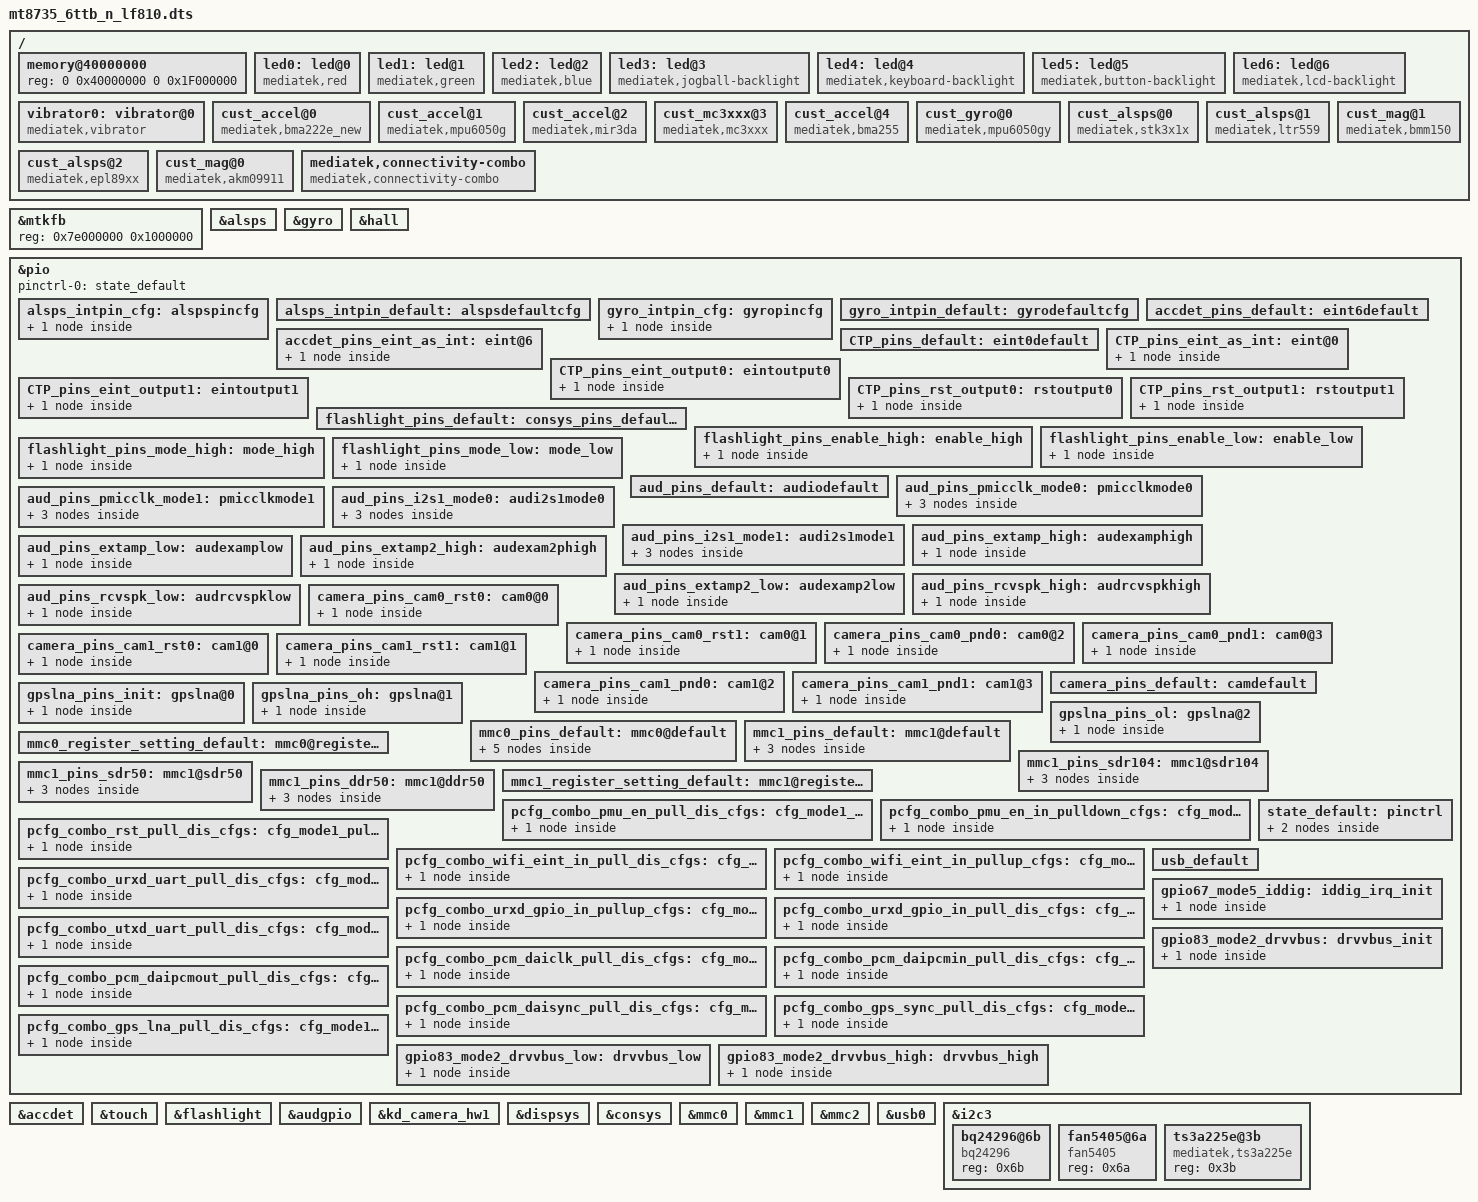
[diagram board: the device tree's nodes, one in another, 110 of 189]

/dts-v1/;

#include "mt6735.dtsi"

#include "cust.dtsi"
#include "cust_eint.dtsi"
#include "mt8735_6ttb_n_bat_setting.dtsi"

/ {
	memory@40000000 {
		device_type = "memory";
		reg = <0 0x40000000 0 0x1F000000>;
	};

	led0:led@0 {
		compatible = "mediatek,red";
		led_mode = <3>;
		data = <1>;
		pwm_config = <0 0 0 0 0>;
	};
	led1:led@1 {
		compatible = "mediatek,green";
		led_mode = <3>;
		data = <2>;
		pwm_config = <0 0 0 0 0>;
	};
	led2:led@2 {
		compatible = "mediatek,blue";
		led_mode = <3>;
		data = <2>;
		pwm_config = <0 0 0 0 0>;
	};
	led3:led@3 {
		compatible = "mediatek,jogball-backlight";
		led_mode = <0>;
		data = <1>;
		pwm_config = <0 0 0 0 0>;
	};
	led4:led@4 {
		compatible = "mediatek,keyboard-backlight";
		led_mode = <0>;
		data = <1>;
		pwm_config = <0 0 0 0 0>;
	};
	led5:led@5 {
		compatible = "mediatek,button-backlight";
		led_mode = <0>;
		data = <1>;
		pwm_config = <0 0 0 0 0>;
	};
	led6:led@6 {
		compatible = "mediatek,lcd-backlight";
		led_mode = <5>;
		data = <1>;
		pwm_config = <0 0 0 0 0>;
	};
	vibrator0:vibrator@0 {
		compatible = "mediatek,vibrator";
		vib_timer = <25>;
		vib_limit = <9>;
		vib_vol= <5>;
	};
	cust_accel@0 {
		compatible = "mediatek,bma222e_new";
		i2c_num = <2>;
		i2c_addr = <0x18 0 0 0>;
		direction = <4>;
		power_id = <0xffff>;
		power_vol = <0>;
		firlen = <16>;
		is_batch_supported = <0>;
	};
        cust_accel@1 {
                compatible = "mediatek,mpu6050g";
                i2c_num = <2>;
                i2c_addr = <0x68 0 0 0>;
                direction = <5>;
                power_id = <0xffff>;
                power_vol = <0>;
                firlen = <16>;
                is_batch_supported = <0>;
        };
        cust_accel@2 {
               compatible = "mediatek,mir3da";
               i2c_num = <2>;
               i2c_addr = <0x26 0 0 0>;
               direction = <7>;             
               power_id = <0xffff>;
               power_vol = <0>;
               firlen = <16>;
               is_batch_supported = <0>;
       };
        cust_mc3xxx@3 {
               compatible = "mediatek,mc3xxx";
               i2c_num = <2>;
               i2c_addr = <0x4c 0 0 0>;
               direction = <4>;
               power_id = <0xffff>;
               power_vol = <0>;
               firlen = <0>;
               is_batch_supported = <0>;
        };
	cust_accel@4 {
		compatible = "mediatek,bma255";
		i2c_num = <2>;
		i2c_addr = <0x10 0 0 0>;
		direction = <4>;
		power_id = <0xffff>;
		power_vol = <0>;
		firlen = <16>;
		is_batch_supported = <0>;
	};
        cust_gyro@0 {
                compatible = "mediatek,mpu6050gy";
                i2c_num = <2>;
                i2c_addr = <0x68 0 0 0>;
                direction = <7>;
                power_id = <0xffff>;
                power_vol = <0>;
                firlen = <16>;
                is_batch_supported = <0>;
        };
        cust_alsps@0 {
                compatible = "mediatek,stk3x1x";
                i2c_num = <2>;
                i2c_addr = <0x48 0 0 0>;
                power_id = <0xffff>;
                power_vol = <0>;
               als_level = <5 9 36 59 82 132 205 273 500 845 1136 1545 2364 4655 6982>;
               als_value= <90 120 145 225 300 550 930 1250 1700 2600 5120 7680 10240 15360 20360 25360>;
               polling_mode_ps = <1>;
               polling_mode_als = <1>;
               ps_threshold_high = <1700>;
               ps_threshold_low = <1500>;
               is_batch_supported_ps = <0>;
               is_batch_supported_als = <0>;
        };
        cust_alsps@1 {
                compatible = "mediatek,ltr559";
                i2c_num = <2>;
                i2c_addr = <0x23 0 0 0>;
		power_id = <0xffff>;
		power_vol = <0>;
               als_level = <5 9 36 59 82 132 205 273 500 845 1136 1545 2364 4655 6982>;
               als_value= <90 120 145 225 300 550 930 1250 1700 2600 5120 7680 10240 15360 20360 25360>;
               polling_mode_ps = <1>;
               polling_mode_als = <1>;
               ps_threshold_high = <1700>;
               ps_threshold_low = <1500>;
		is_batch_supported_ps = <0>;
		is_batch_supported_als = <0>;
	};
	cust_alsps@2 {
        compatible = "mediatek,epl89xx";
        i2c_num = <2>;
        i2c_addr = <0x82 0 0 0>;
        power_id = <0xffff>;
        power_vol = <0>;
        als_level = <20  45  70  90  150  300  500  700  1150  2250  4500  8000  15000  30000  50000>;
        als_value= <10  30  60  80  100  200  400  600  800  1500  3000  6000  10000  20000  40000  60000>;
        polling_mode_ps = <1>;
        polling_mode_als = <1>;
        ps_threshold_high = <4000>;
        ps_threshold_low = <3000>;
        is_batch_supported_ps = <0>;
        is_batch_supported_als = <0>;
    };
	cust_mag@0 {
		compatible				= "mediatek,akm09911";
		i2c_num					= <2>;
		i2c_addr				= <0x0D 0 0 0>;
		direction				= <1>;
		power_id				= <0xffff>;
		power_vol				= <0>;
		is_batch_supported	= <0>;
	};
	cust_mag@1 {
		compatible				= "mediatek,bmm150";
		i2c_num				= <2>;
		i2c_addr				= <0x12 0 0 0>;
		direction				= <1>;
		power_id				= <0xffff>;
		power_vol				= <0>;
		is_batch_supported	= <0>;
	};
/* Connectivity */
	mediatek,connectivity-combo {
		compatible = "mediatek,connectivity-combo";
		/*gpio_combo_ldo_en_pin = <&pio 0xffff 0>;	/*0) GPIO_COMBO_LDO_EN_PIN */
		/*gpio_combo_pmuv28_en_pin = <&pio 0xffff 0>;	/* 1) GPIO_COMBO_PMUV28_EN_PIN */
		gpio_combo_pmu_en_pin = <&pio 21 0>;		/* 2) GPIO_COMBO_PMU_EN_PIN */
		gpio_combo_rst_pin = <&pio 186 0>;		/* 3) GPIO_COMBO_RST_PIN pin */
		/*gpio_combo_bgf_eint_pin = <&pio 0xffff 0>;	/* 4) GPIO_COMBO_BGF_EINT_PIN */
		gpio_wifi_eint_pin = <&pio 20 0>;		/* 5) GPIO_WIFI_EINT_PIN */
		/*gpio_all_eint_pin = <&pio 0xffff 0>;		/* 6) GPIO_ALL_EINT_PIN */
		gpio_combo_urxd_pin = <&pio 66 0>;		/* 7) GPIO_COMBO_URXD_PIN */
		gpio_combo_utxd_pin = <&pio 65 0>;		/* 8) GPIO_COMBO_UTXD_PIN */
		gpio_pcm_daiclk_pin = <&pio 184 0>;		/* 9) GPIO_PCM_DAICLK_PIN */
		gpio_pcm_daipcmin_pin = <&pio 185 0>;		/* 10) GPIO_PCM_DAIPCMIN_PIN */
		gpio_pcm_daipcmout_pin = <&pio 187 0>;		/* 11) GPIO_PCM_DAIPCMOUT_PIN */
		gpio_pcm_daisync_pin = <&pio 188 0>;		/* 12) GPIO_PCM_DAISYNC_PIN */
		/*gpio_combo_i2s_ck_pin = <&pio 0xffff 0>;	/* 13) GPIO_COMBO_I2S_CK_PIN */
		/*gpio_combo_i2s_ws_pin = <&pio 0xffff 0>;	/* 14) GPIO_COMBO_I2S_WS_PIN */
		/*gpio_combo_i2s_dat_pin = <&pio 0xffff 0>;	/* 15) GPIO_COMBO_I2S_DAT_PIN */
		gpio_gps_sync_pin = <&pio 19 0>;	/* 16) GPIO_GPS_SYNC_PIN */
		gpio_gps_lna_pin = <&pio 77 0>;		/* 17) GPIO_GPS_LNA_PIN */
		pinctrl-names = "gpio_pmu_en_pull_dis",
			"gpio_pmu_en_in_pulldown",
			"gpio_rst_pull_dis",
			"gpio_wifi_eint_in_pull_dis",
			"gpio_wifi_eint_in_pullup",
			"gpio_urxd_uart_pull_dis",
			"gpio_urxd_gpio_in_pullup",
			"gpio_urxd_gpio_in_pull_dis",
			"gpio_utxd_uart_pull_dis",
			"gpio_pcm_daiclk_pull_dis",
			"gpio_pcm_daipcmin_pull_dis",
			"gpio_pcm_daipcmout_pull_dis",
			"gpio_pcm_daisync_pull_dis",
			"gpio_gps_sync_pull_dis",
			"gpio_gps_lna_pull_dis";
		pinctrl-0 = <&pcfg_combo_pmu_en_pull_dis_cfgs>;
		pinctrl-1 = <&pcfg_combo_pmu_en_in_pulldown_cfgs>;
		pinctrl-2 = <&pcfg_combo_rst_pull_dis_cfgs>;
		pinctrl-3 = <&pcfg_combo_wifi_eint_in_pull_dis_cfgs>;
		pinctrl-4 = <&pcfg_combo_wifi_eint_in_pullup_cfgs>;
		pinctrl-5 = <&pcfg_combo_urxd_uart_pull_dis_cfgs>;
		pinctrl-6 = <&pcfg_combo_urxd_gpio_in_pullup_cfgs>;
		pinctrl-7 = <&pcfg_combo_urxd_gpio_in_pull_dis_cfgs>;
		pinctrl-8 = <&pcfg_combo_utxd_uart_pull_dis_cfgs>;
		pinctrl-9 = <&pcfg_combo_pcm_daiclk_pull_dis_cfgs>;
		pinctrl-10 = <&pcfg_combo_pcm_daipcmin_pull_dis_cfgs>;
		pinctrl-11 = <&pcfg_combo_pcm_daipcmout_pull_dis_cfgs>;
		pinctrl-12 = <&pcfg_combo_pcm_daisync_pull_dis_cfgs>;
		pinctrl-13 = <&pcfg_combo_gps_sync_pull_dis_cfgs>;
		pinctrl-14 = <&pcfg_combo_gps_lna_pull_dis_cfgs>;
		interrupt-parent = <&eintc>;
		interrupts = < 20 IRQ_TYPE_LEVEL_LOW >;	/* WIFI EINT num is 1 active low level-sensitive */
		debounce = <20 0>;
		status = "okay";
	};
	
};
&mtkfb {
	reg = <0x7e000000 0x1000000>;
};

/* sensor gpio standization */
&alsps {
	pinctrl-names = "pin_default", "pin_cfg";
	pinctrl-0 = <&alsps_intpin_default>;
	pinctrl-1 = <&alsps_intpin_cfg>;
	status = "okay";
};

&gyro {
	pinctrl-names = "pin_default", "pin_cfg";
	pinctrl-0 = <&gyro_intpin_default>;
	pinctrl-1 = <&gyro_intpin_cfg>;
	status = "okay";

};
&hall {
	    interrupts = <1 2>;
	    debounce = <1 128>;
};
/* sensor end */
&pio {
	alsps_intpin_cfg: alspspincfg {

	    pins_cmd_dat {
			pins = <PINMUX_GPIO65__FUNC_GPIO65>;
			slew-rate = <0>;
			bias-pull-up = <00>;
		};
	};

	alsps_intpin_default: alspsdefaultcfg {

	};

	gyro_intpin_cfg: gyropincfg {

	    pins_cmd_dat {
			pins = <PINMUX_GPIO67__FUNC_GPIO67>;
			slew-rate = <0>;
			bias-pull-down = <00>;
		};
	};

	gyro_intpin_default: gyrodefaultcfg {

	};
};

&accdet {
		accdet-mic-vol = <7>;
		headset-mode-setting = <0x500 0x200 1 0x1F0 0x800 0x800 0x20>;
		accdet-plugout-debounce = <20>;
		/*1:ACC mode, 2:low cost without in bias, 6:low cost with in bias*/
		accdet-mic-mode = <1>;
		/*0--MD_MAX--UP_MAX--DW_MAX*/
		headset-three-key-threshold = <0 80 220 500>;
		/*0--MD_MAX--VOICE_MAX--UP_MAX--DW_MAX*/
		headset-four-key-threshold = <0 58 121 192 450>;
		/* ACCDET GPIO standardization ACC mode use */
		pinctrl-names = "default", "state_eint_as_int";
		pinctrl-0 = <&accdet_pins_default>;
		pinctrl-1 = <&accdet_pins_eint_as_int>;
		status = "okay";
};
&pio {
	accdet_pins_default: eint6default {
	};
	accdet_pins_eint_as_int: eint@6 {
		pins_cmd_dat {
			pins = <PINMUX_GPIO6__FUNC_GPIO6>;
			slew-rate = <0>;
			bias-disable;
			/* bias-pull-up = <00>; */
		};
	};
};
&touch {
	tpd-resolution = <800 1280>;
	use-tpd-button = <0>;
	tpd-key-num = <3>;
	tpd-key-local= <139 172 158 0>;
	tpd-key-dim-local = <90 883 100 40 230 883 100 40 370 883 100 40 0 0 0 0>;
	tpd-max-touch-num = <5>;
	tpd-filter-enable = <1>;
	tpd-filter-pixel-density = <93>;
	tpd-filter-custom-prameters = <0 0 0 0 0 0 0 0 0 0 0 0>;
	tpd-filter-custom-speed = <0 0 0>;
	pinctrl-names = "default", "state_eint_as_int", "state_eint_output0", "state_eint_output1",
		"state_rst_output0", "state_rst_output1";
	pinctrl-0 = <&CTP_pins_default>;
	pinctrl-1 = <&CTP_pins_eint_as_int>;
	pinctrl-2 = <&CTP_pins_eint_output0>;
	pinctrl-3 = <&CTP_pins_eint_output1>;
	pinctrl-4 = <&CTP_pins_rst_output0>;
	pinctrl-5 = <&CTP_pins_rst_output1>;
	status = "okay";
};
&pio {

	CTP_pins_default: eint0default {
	};
	CTP_pins_eint_as_int: eint@0 {
		pins_cmd_dat {
			pins = <PINMUX_GPIO10__FUNC_GPIO10>;
			slew-rate = <0>;
			bias-disable;
		};
	};
	CTP_pins_eint_output0: eintoutput0 {
		pins_cmd_dat {
			pins = <PINMUX_GPIO10__FUNC_GPIO10>;
			slew-rate = <1>;
			output-low;
		};
	};
	CTP_pins_eint_output1: eintoutput1 {
		pins_cmd_dat {
			pins = <PINMUX_GPIO10__FUNC_GPIO10>;
			slew-rate = <1>;
			output-high;
		};
	};
	CTP_pins_rst_output0: rstoutput0 {
		pins_cmd_dat {
			pins = <PINMUX_GPIO62__FUNC_GPIO62>;
			slew-rate = <1>;
			output-low;
		};
	};
	CTP_pins_rst_output1: rstoutput1 {
		pins_cmd_dat {
			pins = <PINMUX_GPIO62__FUNC_GPIO62>;
			slew-rate = <1>;
			output-high;
		};
	};
};

/* TOUCH end */

/* flashlight GPIO start */
&flashlight {
	pinctrl-names = "default", "enable_high", "enable_low", "mode_high", "mode_low";
	pinctrl-0 = <&flashlight_pins_default>;
	pinctrl-1 = <&flashlight_pins_enable_high>;
	pinctrl-2 = <&flashlight_pins_enable_low>;
	pinctrl-3 = <&flashlight_pins_mode_high>;
	pinctrl-4 = <&flashlight_pins_mode_low>;
	status = "okay";
};
&pio {
	flashlight_pins_default: default {
	};

	flashlight_pins_enable_high: enable_high {
		pins_cmd_dat {
			pins = <PINMUX_GPIO43__FUNC_GPIO43>;
			slew-rate = <1>;
			output-high;
		};
	};

	flashlight_pins_enable_low: enable_low {
		pins_cmd_dat {
			pins = <PINMUX_GPIO43__FUNC_GPIO43>;
			slew-rate = <1>;
			output-low;
		};
	};
	
	flashlight_pins_mode_high: mode_high {
		pins_cmd_dat {
			pins = <PINMUX_GPIO42__FUNC_GPIO42>;
			slew-rate = <1>;
			output-high;
		};
	};

	flashlight_pins_mode_low: mode_low {
		pins_cmd_dat {
			pins = <PINMUX_GPIO42__FUNC_GPIO42>;
			slew-rate = <1>;
			output-low;
		};
	};
};
/* flashlight GPIO end */
/* AUDIO GPIO standardization */
&audgpio {
	pinctrl-names = "default", "audpmicclk-mode0", "audpmicclk-mode1", "audi2s1-mode0", "audi2s1-mode1", "extamp-pullhigh", "extamp-pulllow", "extamp2-pullhigh", "extamp2-pulllow", "rcvspk-pullhigh", "rcvspk-pulllow";
	pinctrl-0 = <&aud_pins_default>;
	pinctrl-1 = <&aud_pins_pmicclk_mode0>;
	pinctrl-2 = <&aud_pins_pmicclk_mode1>;
	pinctrl-3 = <&aud_pins_i2s1_mode0>;
	pinctrl-4 = <&aud_pins_i2s1_mode1>;
	pinctrl-5 = <&aud_pins_extamp_high>;
	pinctrl-6 = <&aud_pins_extamp_low>;
	pinctrl-7 = <&aud_pins_extamp2_high>;
	pinctrl-8 = <&aud_pins_extamp2_low>;
	pinctrl-9 = <&aud_pins_rcvspk_high>;
	pinctrl-10 = <&aud_pins_rcvspk_low>;
	status = "okay";
};
&pio {
	aud_pins_default: audiodefault {
	};
	aud_pins_pmicclk_mode0: pmicclkmode0 {
		pins_cmd0_dat {
			pins = <PINMUX_GPIO143__FUNC_GPIO143>;
		};
		pins_cmd1_dat {
			pins = <PINMUX_GPIO144__FUNC_GPIO144>;
		};
		pins_cmd2_dat {
			pins = <PINMUX_GPIO145__FUNC_GPIO145>;
		};
	};
	aud_pins_pmicclk_mode1: pmicclkmode1 {
		pins_cmd0_dat {
			pins = <PINMUX_GPIO143__FUNC_AUD_CLK_MOSI>;
		};
		pins_cmd1_dat {
			pins = <PINMUX_GPIO144__FUNC_AUD_DAT_MISO>;
		};
		pins_cmd2_dat {
			pins = <PINMUX_GPIO145__FUNC_AUD_DAT_MOSI>;
		};
	};
	aud_pins_i2s1_mode0: audi2s1mode0 {
		pins_cmd0_dat {
			pins = <PINMUX_GPIO78__FUNC_GPIO78>;
		};
		pins_cmd1_dat {
			pins = <PINMUX_GPIO79__FUNC_GPIO79>;
		};
		pins_cmd2_dat {
			pins = <PINMUX_GPIO80__FUNC_GPIO80>;
		};
	};
	aud_pins_i2s1_mode1: audi2s1mode1 {
		pins_cmd0_dat {
			pins = <PINMUX_GPIO78__FUNC_I2S0_DI>;
		};
		pins_cmd1_dat {
			pins = <PINMUX_GPIO79__FUNC_I2S0_LRCK>;
		};
		pins_cmd2_dat {
			pins = <PINMUX_GPIO80__FUNC_I2S0_BCK>;
		};
	};
	aud_pins_extamp_high: audexamphigh {
		pins_cmd_dat {
			pins = <PINMUX_GPIO63__FUNC_GPIO63>;
			slew-rate = <1>;
			output-high;
		};
	};
	aud_pins_extamp_low: audexamplow {
		pins_cmd_dat {
			pins = <PINMUX_GPIO63__FUNC_GPIO63>;
			slew-rate = <1>;
			output-low;
		};
	};
	aud_pins_extamp2_high: audexam2phigh {
		pins_cmd_dat {
			pins = <PINMUX_GPIO63__FUNC_GPIO63>;
			slew-rate = <1>;
			output-high;
		};
	};
	aud_pins_extamp2_low: audexamp2low {
		pins_cmd_dat {
			pins = <PINMUX_GPIO63__FUNC_GPIO63>;
			slew-rate = <1>;
			output-low;
		};
	};
	aud_pins_rcvspk_high: audrcvspkhigh {
		pins_cmd_dat {
			pins = <PINMUX_GPIO120__FUNC_GPIO120>;
			slew-rate = <1>;
			output-low; /*set low for receiver out*/
		};
	};
	aud_pins_rcvspk_low: audrcvspklow {
		pins_cmd_dat {
			pins = <PINMUX_GPIO120__FUNC_GPIO120>;
			slew-rate = <1>;
			output-high; /*set high for speaker out*/
		};
	};
};
/* AUDIO end */

/* CAMERA GPIO begin */
&pio {
	camera_pins_cam0_rst0: cam0@0 {
	    pins_cmd_dat {
			pins = <PINMUX_GPIO11__FUNC_GPIO11>;/*GPIO_CAMERA_CMRST_PIN*/
			slew-rate = <1>; /*direction 0:in, 1:out*/
			output-low;/*direction out used only. output_low or high*/
		};
	};
	camera_pins_cam0_rst1: cam0@1 {
	    pins_cmd_dat {
			pins = <PINMUX_GPIO11__FUNC_GPIO11>;/*GPIO_CAMERA_CMRST_PIN*/
			slew-rate = <1>;
			output-high;
		};
	};
	camera_pins_cam0_pnd0: cam0@2 {
	    pins_cmd_dat {
			pins = <PINMUX_GPIO7__FUNC_GPIO7>;/*GPIO_CAMERA_CMPDN_PIN*/
			slew-rate = <1>;
			output-low;
		};
	};
	camera_pins_cam0_pnd1: cam0@3 {
	    pins_cmd_dat {
			pins = <PINMUX_GPIO7__FUNC_GPIO7>;/*GPIO_CAMERA_CMPDN_PIN*/
			slew-rate = <1>;
			output-high;
		};
	};
	camera_pins_cam1_rst0: cam1@0 {
	    pins_cmd_dat {
			pins = <PINMUX_GPIO11__FUNC_GPIO11>;/*GPIO_CAMERA_CMRST1_PIN*/
			slew-rate = <1>; /*direction 0:in, 1:out*/
			output-low;/*direction out used only. output_low or high*/
		};
	};
	camera_pins_cam1_rst1: cam1@1 {
	    pins_cmd_dat {
			pins = <PINMUX_GPIO11__FUNC_GPIO11>;/*GPIO_CAMERA_CMRST1_PIN*/
			slew-rate = <1>;
			output-high;
		};
	};
	camera_pins_cam1_pnd0: cam1@2 {
	    pins_cmd_dat {
			pins = <PINMUX_GPIO12__FUNC_GPIO12>;/*GPIO_CAMERA_CMPDN1_PIN*/
			slew-rate = <1>;
			output-low;
		};
	};
	camera_pins_cam1_pnd1: cam1@3 {
		pins_cmd_dat {
			pins = <PINMUX_GPIO12__FUNC_GPIO12>;/*GPIO_CAMERA_CMPDN1_PIN*/
			slew-rate = <1>;
			output-high;
		};
	};
	camera_pins_default: camdefault {

	};
};

&kd_camera_hw1 {
	pinctrl-names = "cam_default", "cam0_rst0", "cam0_rst1", "cam0_pnd0", "cam0_pnd1",
	"cam1_rst0", "cam1_rst1", "cam1_pnd0", "cam1_pnd1";
	pinctrl-0 = <&camera_pins_default>;
	pinctrl-1 = <&camera_pins_cam0_rst0>;
	pinctrl-2 = <&camera_pins_cam0_rst1>;
	pinctrl-3 = <&camera_pins_cam0_pnd0>;
	pinctrl-4 = <&camera_pins_cam0_pnd1>;
	pinctrl-5 = <&camera_pins_cam1_rst0>;
	pinctrl-6 = <&camera_pins_cam1_rst1>;
	pinctrl-7 = <&camera_pins_cam1_pnd0>;
	pinctrl-8 = <&camera_pins_cam1_pnd1>;
	status = "okay";

};
/* CAMERA GPIO end */

/* LCM GPIO set */
&dispsys {
	lcm_power_gpio = <&pio 1 0>;
	lcm_bl_gpio = <&pio 3 0>;
};
/* LCM end */

/* CONSYS GPIO standardization */
&pio {
	consys_pins_default: default {

	};

	gpslna_pins_init: gpslna@0 {

	    pins_cmd_dat {
			pins = <PINMUX_GPIO79__FUNC_GPIO79>;
			slew-rate = <0>;
			bias-disable;
			output-low;
		};
	};

	gpslna_pins_oh: gpslna@1 {

	    pins_cmd_dat {
			pins = <PINMUX_GPIO79__FUNC_GPIO79>;
			slew-rate = <1>;
			output-high;
		};
	};

	gpslna_pins_ol: gpslna@2 {

	    pins_cmd_dat {
			pins = <PINMUX_GPIO79__FUNC_GPIO79>;
			slew-rate = <1>;
			output-low;
		};
	};

};

&consys {
	pinctrl-names = "default", "gps_lna_state_init", "gps_lna_state_oh", "gps_lna_state_ol";
	pinctrl-0 = <&consys_pins_default>;
	pinctrl-1 = <&gpslna_pins_init>;
	pinctrl-2 = <&gpslna_pins_oh>;
	pinctrl-3 = <&gpslna_pins_ol>;
	status = "okay";

};
/* CONSYS end */

/* mmc start */
&mmc0 {
		clk_src = /bits/ 8 <MSDC50_CLKSRC_400MHZ>;
		bus-width = <8>;
		max-frequency = <200000000>;
		cap-mmc-highspeed;
		msdc-sys-suspend;
		mmc-ddr-1_8v;
		non-removable;
		pinctl = <&mmc0_pins_default>;
		register_setting = <&mmc0_register_setting_default>;
		host_function = /bits/ 8 <MSDC_EMMC>;
		bootable;
		status = "okay";
};

&mmc1 {
		clk_src = /bits/ 8 <MSDC30_CLKSRC_200MHZ>;
		bus-width = <4>;
		max-frequency = <200000000>;
		msdc-sys-suspend;
		cap-sd-highspeed;
		sd-uhs-sdr12;
		sd-uhs-sdr25;
		sd-uhs-sdr50;
		sd-uhs-sdr104;
		sd-uhs-ddr50;
		pinctl = <&mmc1_pins_default>;
		pinctl_sdr104 = <&mmc1_pins_sdr104>;
		pinctl_sdr50 = <&mmc1_pins_sdr50>;
		pinctl_ddr50 = <&mmc1_pins_ddr50>;
		register_setting = <&mmc1_register_setting_default>;
		host_function = /bits/ 8 <MSDC_SD>;
		cd_level = /bits/ 8 <MSDC_CD_LOW>;
		cd-gpios = <&pio 5 0>;
		status = "okay";
};

&mmc2 {
		clk_src = /bits/ 8 <MSDC30_CLKSRC_200MHZ>;
		bus-width = <4>;
		max-frequency = <200000000>;
		cap-sd-highspeed;
		sd-uhs-sdr12;
		sd-uhs-sdr25;
		sd-uhs-sdr50;
		sd-uhs-sdr104;
		sd-uhs-ddr50;
		non-removable;
		host_function = /bits/ 8 <MSDC_SDIO>;
		status = "okay";
};

&pio {
	mmc0_pins_default: mmc0@default {
			pins_cmd {
				drive-strength = /bits/ 8 <2>;
			};
			pins_dat {
				drive-strength = /bits/ 8 <2>;
			};
			pins_clk {
				drive-strength = /bits/ 8 <2>;
			};
			pins_rst {
				drive-strength = /bits/ 8 <2>;
			};
			pins_ds {
				drive-strength = /bits/ 8 <2>;
			};
	};

	mmc0_register_setting_default: mmc0@register_default {
		dat0rddly      = /bits/ 8 <0>;
		dat1rddly      = /bits/ 8 <0>;
		dat2rddly      = /bits/ 8 <0>;
		dat3rddly      = /bits/ 8 <0>;
		dat4rddly      = /bits/ 8 <0>;
		dat5rddly      = /bits/ 8 <0>;
		dat6rddly      = /bits/ 8 <0>;
		dat7rddly      = /bits/ 8 <0>;
		datwrddly      = /bits/ 8 <0>;
		cmdrrddly      = /bits/ 8 <0>;
		cmdrddly       = /bits/ 8 <0>;
		cmd_edge = /bits/ 8 <MSDC_SMPL_FALLING>;
		rdata_edge = /bits/ 8 <MSDC_SMPL_FALLING>;
		wdata_edge = /bits/ 8 <MSDC_SMPL_FALLING>;

		ett-hs200-cells = <12>;
		ett-hs200-default = <OFFSET_MSDC_PATCH_BIT0	MSDC_PB0_INT_DAT_LATCH_CK_SEL 0x0
			OFFSET_MSDC_PATCH_BIT0	MSDC_PB0_CKGEN_MSDC_DLY_SEL   0x0
			OFFSET_MSDC_PATCH_BIT1	MSDC_PB1_CMD_RSP_TA_CNTR      0x1
			OFFSET_MSDC_IOCON		MSDC_IOCON_RSPL               0x0
			OFFSET_MSDC_PAD_TUNE0	MSDC_PAD_TUNE0_CMDRDLY        0x7
			OFFSET_MSDC_PAD_TUNE0	MSDC_PAD_TUNE0_CMDRRDLY       0xb
			OFFSET_MSDC_PATCH_BIT1		MSDC_PB1_WRDAT_CRCS_TA_CNTR   0x1
			OFFSET_MSDC_PAD_TUNE0	MSDC_PAD_TUNE0_DATWRDLY       0xb
			OFFSET_MSDC_IOCON			MSDC_IOCON_W_D0SPL            0x0
			OFFSET_MSDC_DAT_RDDLY0		MSDC_DAT_RDDLY0_D0            0x7
			OFFSET_MSDC_PAD_TUNE0	MSDC_PAD_TUNE0_DATRRDLY       0x9
			OFFSET_MSDC_IOCON		MSDC_IOCON_R_D_SMPL           0x0>;

		ett-hs400-cells = <8>;
		ett-hs400-default = <OFFSET_MSDC_PATCH_BIT0	MSDC_PB0_INT_DAT_LATCH_CK_SEL	0x0
			OFFSET_MSDC_PATCH_BIT0		MSDC_PB0_CKGEN_MSDC_DLY_SEL		0x0
			OFFSET_EMMC50_PAD_DS_TUNE	MSDC_EMMC50_PAD_DS_TUNE_DLY1	0x2
			OFFSET_EMMC50_PAD_DS_TUNE	MSDC_EMMC50_PAD_DS_TUNE_DLY3	0x10
			OFFSET_MSDC_PATCH_BIT1			MSDC_PB1_CMD_RSP_TA_CNTR	0x1
			OFFSET_MSDC_IOCON		MSDC_IOCON_RSPL				0x0
			OFFSET_MSDC_PAD_TUNE0			MSDC_PAD_TUNE0_CMDRDLY		0x6
			OFFSET_MSDC_PAD_TUNE0		MSDC_PAD_TUNE0_CMDRRDLY		0x6>;
	};

	mmc1_pins_default: mmc1@default {
			pins_cmd {
				drive-strength = /bits/ 8 <3>;
			};
			pins_dat {
				drive-strength = /bits/ 8 <3>;
			};
			pins_clk {
				drive-strength = /bits/ 8 <3>;
			};
	};

	mmc1_pins_sdr104: mmc1@sdr104 {
			pins_cmd {
				drive-strength = /bits/ 8 <2>;
			};
			pins_dat {
				drive-strength = /bits/ 8 <2>;
			};
			pins_clk {
				drive-strength = /bits/ 8 <3>;
			};
	};

	mmc1_pins_sdr50: mmc1@sdr50 {
			pins_cmd {
				drive-strength = /bits/ 8 <2>;
			};
			pins_dat {
				drive-strength = /bits/ 8 <2>;
			};
			pins_clk {
				drive-strength = /bits/ 8 <3>;
			};
	};

	mmc1_pins_ddr50: mmc1@ddr50 {
			pins_cmd {
				drive-strength = /bits/ 8 <2>;
			};
			pins_dat {
				drive-strength = /bits/ 8 <2>;
			};
			pins_clk {
				drive-strength = /bits/ 8 <3>;
			};
	};

	mmc1_register_setting_default: mmc1@register_default {
				dat0rddly      = /bits/ 8 <0>;
				dat1rddly      = /bits/ 8 <0>;
				dat2rddly      = /bits/ 8 <0>;
				dat3rddly      = /bits/ 8 <0>;
				datwrddly      = /bits/ 8 <0>;
				cmdrrddly      = /bits/ 8 <0>;
				cmdrddly       = /bits/ 8 <0>;
				cmd_edge = /bits/ 8 <MSDC_SMPL_FALLING>;
				rdata_edge = /bits/ 8 <MSDC_SMPL_FALLING>;
				wdata_edge = /bits/ 8 <MSDC_SMPL_FALLING>;
	};
};
/* mmc end */
	/* ++++++ Connectivity GPIO configs ++++++ */
&pio {
	pinctrl-names = "default";
	pinctrl-0 = <&state_default>;
	pcfg_combo_pmu_en_pull_dis_cfgs:cfg_mode1_pull_dis {
		combo_pins {
			pinmux = <PINMUX_GPIO21__FUNC_GPIO21>;
			bias-disable;
		};
	};

	pcfg_combo_pmu_en_in_pulldown_cfgs:cfg_mode1_in_pulldown {
		combo_pins {
			pinmux = <PINMUX_GPIO21__FUNC_GPIO21>;
			bias-pull-down;
		};
	};

	pcfg_combo_rst_pull_dis_cfgs:cfg_mode1_pull_dis {
		combo_pins {
			pinmux = <PINMUX_GPIO186__FUNC_GPIO186>;
			bias-disable;
		};
	};

	pcfg_combo_wifi_eint_in_pull_dis_cfgs:cfg_mode1_in_pull_dis {
		combo_pins {
			pinmux = <PINMUX_GPIO20__FUNC_GPIO20>;
			input-enable;
			bias-disable;
		};
	};
	pcfg_combo_wifi_eint_in_pullup_cfgs:cfg_mode1_in_pullup {
		combo_pins {
			pinmux = <PINMUX_GPIO20__FUNC_GPIO20>;
			input-enable;
			bias-pull-up;
		};
	};

	pcfg_combo_urxd_uart_pull_dis_cfgs:cfg_mode2_pull_dis {
		combo_pins {
			pinmux = <PINMUX_GPIO66__FUNC_PTA_TXD>;
			bias-disable;
		};
	};
	pcfg_combo_urxd_gpio_in_pullup_cfgs:cfg_mode1_in_pullup {
		combo_pins {
			pinmux = <PINMUX_GPIO66__FUNC_PTA_TXD>;
			input-enable;
			bias-pull-up;
		};
	};
	pcfg_combo_urxd_gpio_in_pull_dis_cfgs:cfg_mode1_in_pull_dis {
		combo_pins {
			pinmux = <PINMUX_GPIO65__FUNC_PTA_RXD>;
			input-enable;
			bias-disable;
		};
	};

	pcfg_combo_utxd_uart_pull_dis_cfgs:cfg_mode2_pull_dis {
		combo_pins {
			pinmux = <PINMUX_GPIO65__FUNC_PTA_RXD>;
			bias-disable;
		};
	};

	pcfg_combo_pcm_daiclk_pull_dis_cfgs:cfg_mode3_pull_dis {
		combo_pins {
			pinmux = <PINMUX_GPIO184__FUNC_PCM0_CLK>;
			bias-disable;
		};
	};

	pcfg_combo_pcm_daipcmin_pull_dis_cfgs:cfg_mode3_pull_dis {
		combo_pins {
			pinmux = <PINMUX_GPIO185__FUNC_PCM0_DI>;
			bias-disable;
		};
	};

	pcfg_combo_pcm_daipcmout_pull_dis_cfgs:cfg_mode3_pull_dis {
		combo_pins {
			pinmux = <PINMUX_GPIO187__FUNC_PCM0_DO>;
			bias-disable;
		};
	};

	pcfg_combo_pcm_daisync_pull_dis_cfgs:cfg_mode3_pull_dis {
		combo_pins {
			pinmux = <PINMUX_GPIO188__FUNC_PCM0_SYNC>;
			bias-disable;
		};
	};

	pcfg_combo_gps_sync_pull_dis_cfgs:cfg_mode1_pull_dis {
		combo_pins {
			pinmux = <PINMUX_GPIO19__FUNC_GPS_FRAME_SYNC>;
			bias-disable;
		};
	};
	pcfg_combo_gps_lna_pull_dis_cfgs:cfg_mode1_pull_dis {
		combo_pins {
			pinmux = <PINMUX_GPIO77__FUNC_GPIO77>;
			bias-disable;
		};
	};

	state_default:pinctrl {
		/* ++++++ Connectivity GPIO configs ++++++ */
		combo_wifi_eint_pins {
			pinmux = <PINMUX_GPIO20__FUNC_GPIO20>;
			bias-pull-up;
		};

		combo_pcm_pins {
			pinmux = <PINMUX_GPIO184__FUNC_MRG_CLK>,
				   <PINMUX_GPIO185__FUNC_MRG_DI>,
				   <PINMUX_GPIO187__FUNC_MRG_DO>,
				   <PINMUX_GPIO188__FUNC_MRG_SYNC>;
			bias-disable;
		};
		/* ----- Connectivity GPIO configs ----- */
	};
	/* ------ Connectivity GPIO configs ------ */
};
/* USB GPIO Kernal Standardization start */
&pio {
	usb_default: usb_default {
	};

	gpio67_mode5_iddig: iddig_irq_init {
		pins_cmd_dat {
			pins = <PINMUX_GPIO67__FUNC_IDDIG>;
			slew-rate = <0>;
			bias-pull-up = <00>;
		};
	};

	gpio83_mode2_drvvbus: drvvbus_init {
		pins_cmd_dat {
			pins = <PINMUX_GPIO83__FUNC_USB_DRVVBUS>;
			slew-rate = <1>;
			bias-pull-up = <00>;
		};
	};

	gpio83_mode2_drvvbus_low: drvvbus_low {
		pins_cmd_dat {
			pins = <PINMUX_GPIO83__FUNC_USB_DRVVBUS>;
			slew-rate = <1>;
			output-low;
		};
	};

	gpio83_mode2_drvvbus_high: drvvbus_high {
		pins_cmd_dat {
			pins = <PINMUX_GPIO83__FUNC_USB_DRVVBUS>;
			slew-rate = <1>;
			output-high;
		};
	};
};

&usb0 {
	iddig_gpio = <67 1>;
	pinctrl-names = "usb_default", "iddig_irq_init", "drvvbus_init", "drvvbus_low", "drvvbus_high";
	pinctrl-0 = <&usb_default>;
	pinctrl-1 = <&gpio67_mode5_iddig>;
	pinctrl-2 = <&gpio83_mode2_drvvbus>;
	pinctrl-3 = <&gpio83_mode2_drvvbus_low>;
	pinctrl-4 = <&gpio83_mode2_drvvbus_high>;
	status = "okay";
};
/* USB GPIO Kernal Standardization end */

/* i2c start */
&i2c3 {
	bq24296@6b {
		status = "okay";
		compatible = "bq24296";
		reg = <0x6b>;
	};

        fan5405@6a {
                status = "okay";
                compatible = "fan5405";
                reg = <0x6a>;
        };

	ts3a225e@3b {
		compatible = "mediatek,ts3a225e";
		reg = <0x3b>;
		status = "okay";
	};
};
/* i2c end */
